# STM32H7B3x register map
File version: 2.0
CPU: CM7 r0p1, little endian, MPU, FPU, 4 interrupt priority bits
Registers are 32-bit, read-write, reset 0x0 unless marked. A register's access mark holds for its fields unless they carry their own. Offsets are from the block's base; [hi:lo] are bit positions; {n}, {i} and the like mark numbered series.

## CRC — Cryptographic processor
Base 0x40023000
0x00 DR reset 0xFFFFFFFF — Data register
  [31:0] DR — Data Register
0x04 IDR — Independent Data register
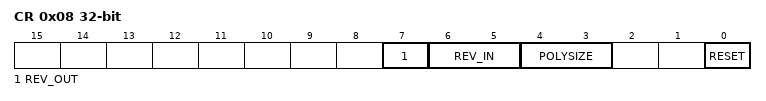
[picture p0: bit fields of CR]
0x08 CR access per field — Control register
  [7] REV_OUT rw — Reverse output data
  [6:5] REV_IN rw — Reverse input data
  [4:3] POLYSIZE rw — Polynomial size
  [0] RESET wo — RESET bit
0x0C INIT — Initial CRC value
  [31:0] CRC_INIT — Programmable initial CRC value
0x10 POL — CRC polynomial
  [31:0] POL — Programmable polynomial

## CRYP — Cryptographic processor
Base 0x48021000
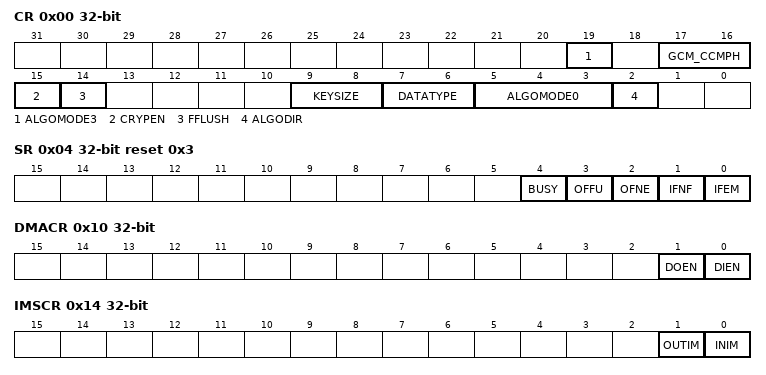
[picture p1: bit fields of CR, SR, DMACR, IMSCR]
0x00 CR access per field — control register
  [19] ALGOMODE3 rw — ALGOMODE
  [17:16] GCM_CCMPH rw
  [15] CRYPEN rw — Cryptographic processor enable
  [14] FFLUSH wo — FIFO flush
  [9:8] KEYSIZE rw — Key size selection (AES mode only)
  [7:6] DATATYPE rw — Data type selection
  [5:3] ALGOMODE0 rw — Algorithm mode
  [2] ALGODIR rw — Algorithm direction
0x04 SR ro reset 0x3 — status register
  [4] BUSY — Busy bit
  [3] OFFU — Output FIFO full
  [2] OFNE — Output FIFO not empty
  [1] IFNF — Input FIFO not full
  [0] IFEM — Input FIFO empty
0x08 DIN — data input register
  [31:0] DATAIN — Data input
0x0C DOUT ro — data output register
  [31:0] DATAOUT — Data output
0x10 DMACR — DMA control register
  [1] DOEN — DMA output enable
  [0] DIEN — DMA input enable
0x14 IMSCR — interrupt mask set/clear register
  [1] OUTIM — Output FIFO service interrupt mask
  [0] INIM — Input FIFO service interrupt mask
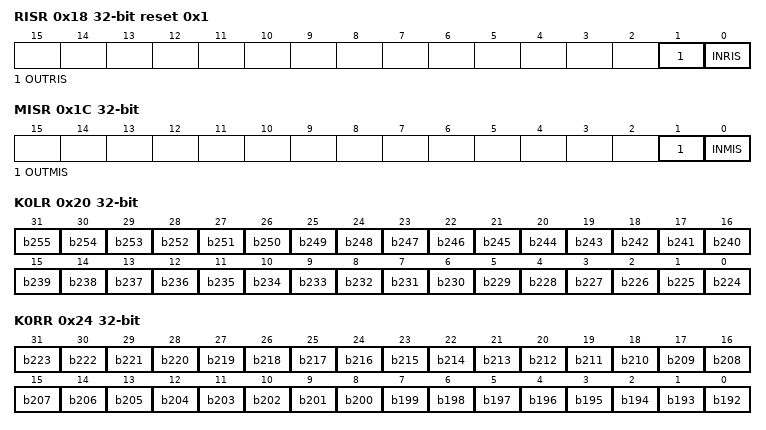
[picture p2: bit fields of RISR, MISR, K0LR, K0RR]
0x18 RISR ro reset 0x1 — raw interrupt status register
  [1] OUTRIS — Output FIFO service raw interrupt status
  [0] INRIS — Input FIFO service raw interrupt status
0x1C MISR ro — masked interrupt status register
  [1] OUTMIS — Output FIFO service masked interrupt status
  [0] INMIS — Input FIFO service masked interrupt status
0x20 K0LR wo — key registers
  [n-224] b{n} (n=224..255)
0x24 K0RR wo — key registers
  [n-192] b{n} (n=192..223)
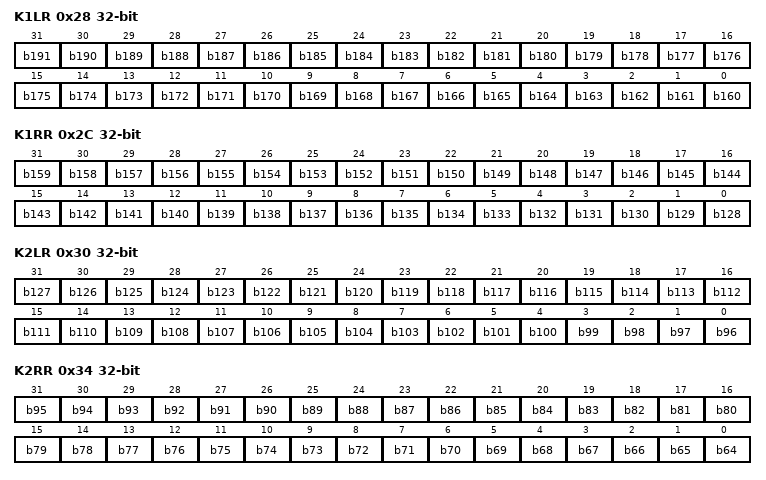
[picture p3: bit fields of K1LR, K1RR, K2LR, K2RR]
0x28 K1LR wo — key registers
  [n-160] b{n} (n=160..191)
0x2C K1RR wo — key registers
  [n-128] b{n} (n=128..159)
0x30 K2LR wo — key registers
  [n-96] b{n} (n=96..127)
0x34 K2RR wo — key registers
  [n-64] b{n} (n=64..95)
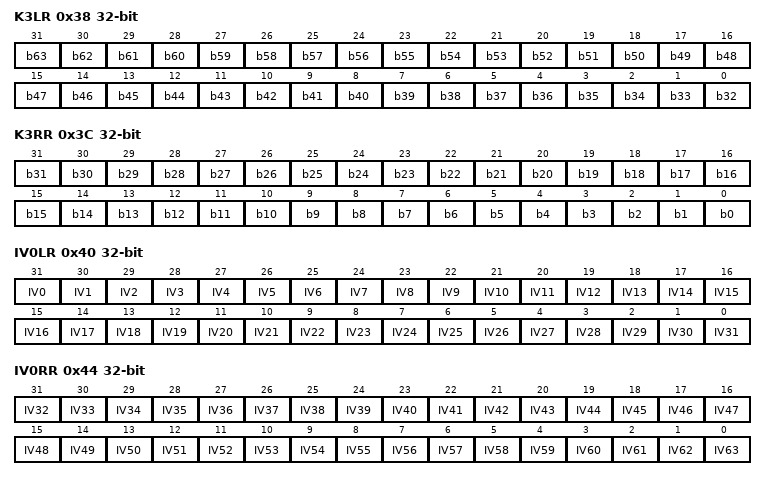
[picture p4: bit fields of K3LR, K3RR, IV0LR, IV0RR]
0x38 K3LR wo — key registers
  [n-32] b{n} (n=32..63)
0x3C K3RR wo — key registers
  [n] b{n} (n=0..31)
0x40 IV0LR — initialization vector registers
  [31-n] IV{n} (n=0..31)
0x44 IV0RR — initialization vector registers
  [63-n] IV{n} (n=32..63)
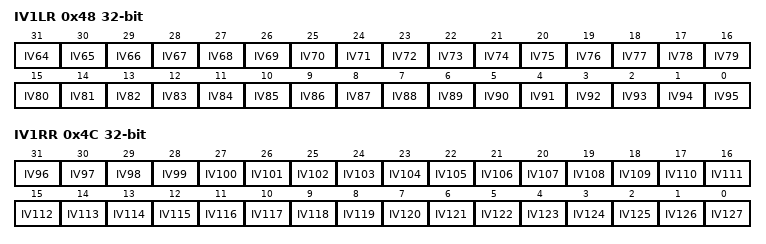
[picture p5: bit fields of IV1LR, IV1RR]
0x48 IV1LR — initialization vector registers
  [95-n] IV{n} (n=64..95)
0x4C IV1RR — initialization vector registers
  [127-n] IV{n} (n=96..127)
{0x50+4i} CSGCMCCM{i}R (i=0..7) — context swap register
{0x70+4i} CSGCM{i}R (i=0..7) — context swap register

## DBGMCU — Microcontroller Debug Unit
Base 0x5C001000
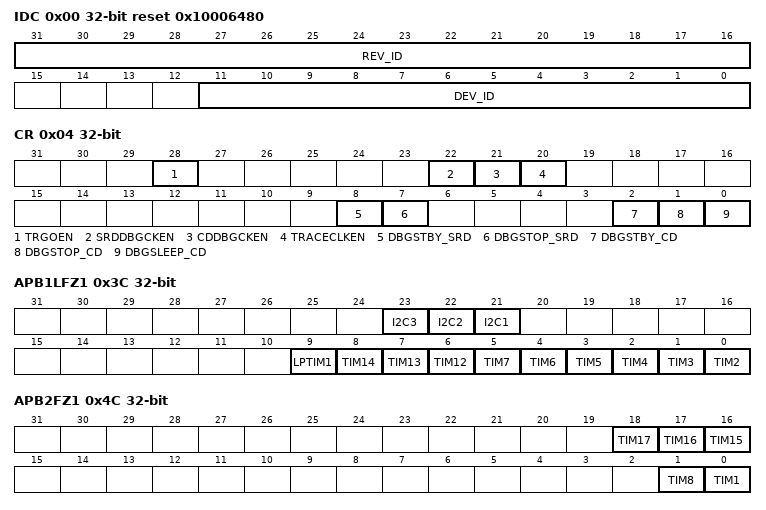
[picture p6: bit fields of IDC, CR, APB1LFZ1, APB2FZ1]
0x00 IDC ro reset 0x10006480 — DBGMCU Identity Code Register
  [31:16] REV_ID — Revision
  [11:0] DEV_ID — Device ID
0x04 CR — DBGMCU Configuration Register
  [28] TRGOEN — External trigger output enable
  [22] SRDDBGCKEN — SmartRun domain debug clock enable
  [21] CDDBGCKEN — CPU domain debug clock enable
  [20] TRACECLKEN — Trace port clock enable
  [8] DBGSTBY_SRD — debug in SmartRun domain Standby mode
  [7] DBGSTOP_SRD — debug in SmartRun domain Stop mode
  [2] DBGSTBY_CD — Allow D1 domain debug in Standby mode
  [1] DBGSTOP_CD — Allow D1 domain debug in Stop mode
  [0] DBGSLEEP_CD — Allow D1 domain debug in Sleep mode
0x34 APB3FZ1 — DBGMCU APB3 peripheral freeze register
  [6] WWDG — WWDG stop in debug
0x3C APB1LFZ1 — DBGMCU APB1L peripheral freeze register
  [23] I2C3 — I2C3 SMBUS timeout stop in debug
  [22] I2C2 — I2C2 SMBUS timeout stop in debug
  [21] I2C1 — I2C1 SMBUS timeout stop in debug
  [9] LPTIM1 — LPTIM1 stop in debug
  [8] TIM14 — TIM14 stop in debug
  [7] TIM13 — TIM13 stop in debug
  [6] TIM12 — TIM12 stop in debug
  [n-2] TIM{n} (n=2..7) — TIM{n} stop in debug
0x4C APB2FZ1 — DBGMCU APB2 peripheral freeze register
  [18] TIM17 — TIM17 stop in debug
  [17] TIM16 — TIM16 stop in debug
  [16] TIM15 — TIM15 stop in debug
  [1] TIM8 — TIM8 stop in debug
  [0] TIM1 — TIM1 stop in debug
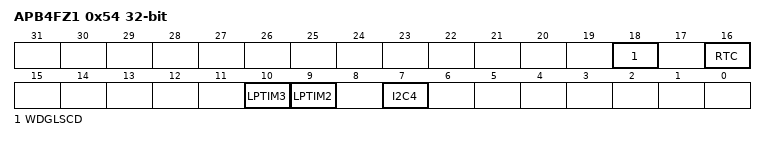
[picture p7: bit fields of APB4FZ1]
0x54 APB4FZ1 — DBGMCU APB4 peripheral freeze register
  [18] WDGLSCD — LS watchdog for CPU domain stop in debug
  [16] RTC — RTC stop in debug
  [10] LPTIM3 — LPTIM3 stop in debug
  [9] LPTIM2 — LPTIM2 stop in debug
  [7] I2C4 — I2C4 SMBUS timeout stop in debug
